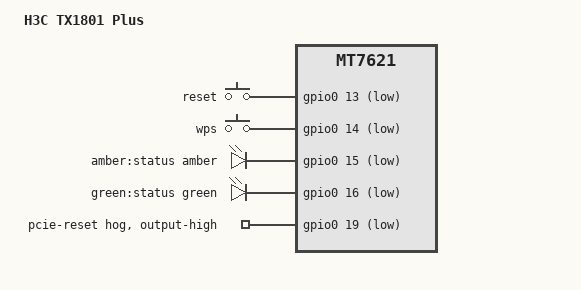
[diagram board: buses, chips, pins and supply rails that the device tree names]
// SPDX-License-Identifier: GPL-2.0-or-later

#include "mt7621.dtsi"

#include <dt-bindings/gpio/gpio.h>
#include <dt-bindings/input/input.h>
#include <dt-bindings/leds/common.h>

/ {
	compatible = "h3c,tx1801-plus", "mediatek,mt7621-soc";
	model = "H3C TX1801 Plus";

	aliases {
		serial0 = &uart0;
	};

	chosen {
		stdout-path = &uart0;
	};

	config {
		reset-button = "reset";
		wps-button = "wps";
		status1-led = "green:status";
		status2-led = "amber:status";
	};

	gpio-keys {
		compatible = "gpio-keys";

		reset {
			label = "reset";
			gpios = <&gpio0 13 GPIO_ACTIVE_LOW>;
			linux,code = <KEY_RESTART>;
		};

		wps {
			label = "wps";
			gpios = <&gpio0 14 GPIO_ACTIVE_LOW>;
			linux,code = <KEY_WPS_BUTTON>;
		};
	};

	gpio-leds {
		compatible = "gpio-leds";

		led-amber {
			label = "amber:status";
			color = <LED_COLOR_ID_AMBER>;
			function = LED_FUNCTION_STATUS;
			gpios = <&gpio0 15 GPIO_ACTIVE_LOW>;
			default-state = "off";
		};

		led-green {
			label = "green:status";
			color = <LED_COLOR_ID_GREEN>;
			function = LED_FUNCTION_STATUS;
			gpios = <&gpio0 16 GPIO_ACTIVE_LOW>;
			default-state = "on";
		};
	};
};

&gpio0 {
	pcie-reset {
		gpio-hog;
		gpios = <19 GPIO_ACTIVE_LOW>;
		output-high;
	};
};

&state_default {
	/delete-node/ rgmii2-gpio_pins;
	/delete-node/ sdxc-gpio_pins;
};
